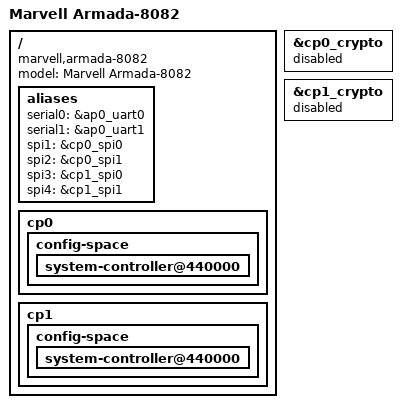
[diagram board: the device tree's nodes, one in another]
// SPDX-License-Identifier: (GPL-2.0+ OR MIT)
/*
 * Copyright (C) 2018 Marvell Technology Group Ltd.
 *
 * Device Tree file for Marvell Armada-8082 SoC, made of one AP810 and
 * two CP110.
 */

#include "armada-common.dtsi"
#include "armada-8kp.dtsi"
#include "armada-ap810-ap0.dtsi"

#define AP_NUM					0
#define AP810_BASE				0xe8000000
#define AP810_GIC_ITS_BASE			0xf040000

#include "armada-ap810-octa-core.dtsi"

/* AP0 CP0 IO
 * 0x81_0000_0000 - 0x81_ffff_ffff - internal CFG (4GB)
 * 0x82_0000_0000 - 0x83_ffff_ffff - PEX0 (8GB)
 * 0x84_0000_0000 - 0x85_ffff_ffff - PEX1 (8GB)
 * 0x86_0000_0000 - 0x87_ffff_ffff - PEX2 (8GB)
 */
#define CP110_NUM				0

#include "armada-cp110.dtsi"

#undef CP110_NUM

/* AP0 CP1 IO
 * 0x88_0000_0000 - 0x88_ffff_ffff - internal CFG (4GB)
 * 0x89_0000_0000 - 0x8a_ffff_ffff - PEX0 (8GB)
 * 0x8b_0000_0000 - 0x8c_ffff_ffff - PEX1 (8GB)
 * 0x8d_0000_0000 - 0x8e_ffff_ffff - PEX2 (8GB)
 */
#define CP110_NUM				1

#include "armada-cp110.dtsi"

#undef CP110_NUM

/* AP810 definitions are used in CP110 dtsi files, so un-define them after defining it's connected CPs */
#undef AP_NUM
#undef AP810_BASE
#undef AP810_GIC_ITS_BASE

/ {
	model = "Marvell Armada-8082";
	compatible = "marvell,armada-8082", "marvell,armada-ap810-octa",
				"marvell,armada-ap810";

	aliases {
		serial0 = &ap0_uart0;
		serial1 = &ap0_uart1;
		spi1 = &cp0_spi0;
		spi2 = &cp0_spi1;
		spi3 = &cp1_spi0;
		spi4 = &cp1_spi1;
	};

	/* Delete unsupported interfaces from CP nodes:
	 *	1. GPIO in CP requires a pinctrl driver support,
	 *	   which is currently not suitable for AP810.
	 */
	cp0 {
		config-space {
			system-controller@440000 {
				/delete-node/ gpio@100;
				/delete-node/ gpio@140;
			};
		};
	};
	cp1 {
		config-space {
			system-controller@440000 {
				/delete-node/ gpio@100;
				/delete-node/ gpio@140;
			};
		};
	};
};

&cp0_crypto {
	status = "disabled";
};

&cp1_crypto {
	status = "disabled";
};
